# MM32SPIN0230 register map
Series: ARM Cortex M0; File version: 1.0
ARM 32-bit Cortex-M0 based device.
CPU: CM0 r0p0, little endian, no MPU, no FPU, 2 interrupt priority bits
Registers are 32-bit, read-write, reset 0x0 unless marked. A register's access mark holds for its fields unless they carry their own. Offsets are from the block's base; lines under a group give offsets from that group; [hi:lo] are bit positions; {n}, {i} and the like mark numbered series; 'fields as' and 'values as' point back to an identical list; <NAME> marks a mode.

## Memory map
0x40000000 TIM2 size 0x400
0x40001000 TIM6 size 0x400
0x40001800 TIM13 size 0x400
0x40003000 IWDG size 0x400
0x40007000 PWR size 0x400
0x40009000 OPAMP1 size 0x400
0x40009400 OPAMP2 size 0x400
0x40010000 SYSCFG size 0x400
0x40010400 EXTI size 0x400
0x40010C00 USART1 size 0x400
0x40012400 ADC1 size 0x400
0x40012C00 TIM1 size 0x400
0x40013400 DBGMCU size 0x400
0x40013C00 COMP size 0x400
0x40014000 TIM14 size 0x400
0x40020000 DMA size 0x400
0x40021000 RCC size 0x400
0x40022000 FLASH size 0x400
0x40030000 HWDIV size 0x400
0x48000000 GPIOA size 0x400
0x48000400 GPIOB size 0x400

## Interrupts
0 IWDG — independent watchdog interrupt connected to EXTI24
3 FLASH — Flash global interrupt
4 RCC — RCC global interrupt
5 EXTI0_1 (EXTI) — EXTI line [1:0] interrupt
6 EXTI3_2 (EXTI) — EXTI line [3:2] interrupt
7 EXTI15_4 (EXTI) — EXTI line [15:4] interrupt
8 HWDIV — Hard_Divider interrupt
9 DMA1_CH1 (DMA) — DMA1 channel 1 global interrupt
10 DMA1_CH3_CH2 (DMA) — DMA1 channel [3:2] global interrupt
13 TIM1_BRK_UP_TRG_COM (TIM1) — TIM1 break, update, trigger, COM interrupt
14 TIM1_CC (TIM1) — TIM1 capture compare interrupt
15 TIM2 — TIM2 global interrupt
16 TIM6 — TIM6 global interrupt
21 TIM13 — TIM13 global interrupt
22 TIM14 — TIM14 global interrupt
25 COMP1_2 (COMP) — Comparator 1/2 output connected to EXTI19 and EXTI20
28 USART1 — USART1 global interrupt

## ADC1
Base 0x40012400
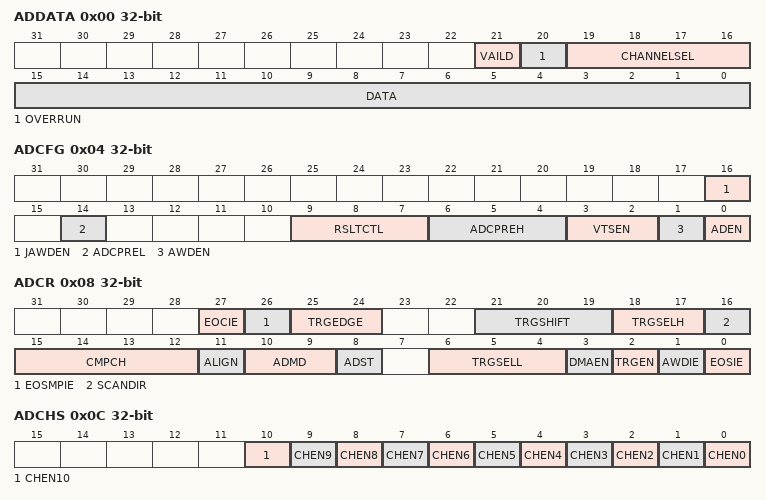
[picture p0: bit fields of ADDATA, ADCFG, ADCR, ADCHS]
0x00 ADDATA ro — Data Register
  [21] VAILD, [20] OVERRUN, [19:16] CHANNELSEL, [15:0] DATA
0x04 ADCFG — Configuration Register
  [16] JAWDEN, [14] ADCPREL, [9:7] RSLTCTL, [6:4] ADCPREH, [3:2] VTSEN, [1] AWDEN, [0] ADEN
0x08 ADCR — Control Register
  [27] EOCIE, [26] EOSMPIE, [25:24] TRGEDGE, [21:19] TRGSHIFT, [18:17] TRGSELH, [16] SCANDIR, [15:12] CMPCH, [11] ALIGN, [10:9] ADMD, [8] ADST, [6:4] TRGSELL, [3] DMAEN, [2] TRGEN, [1] AWDIE, [0] EOSIE
0x0C ADCHS — Channel Selection Register
  [n] CHEN{n} (n=0..10)
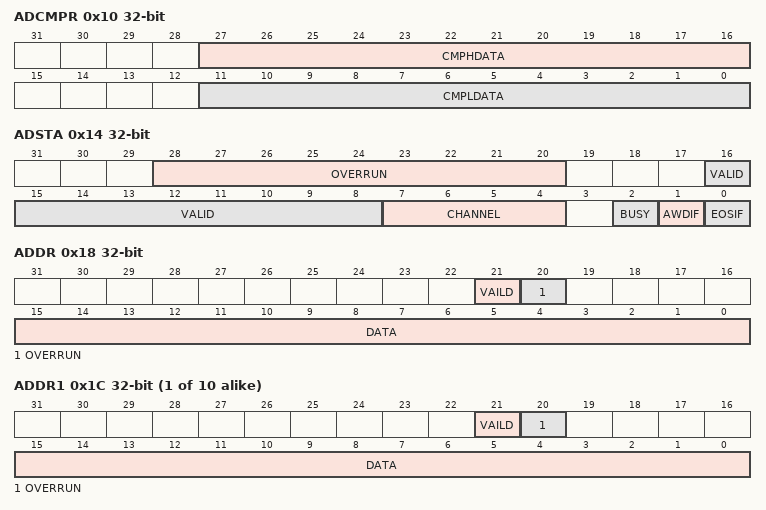
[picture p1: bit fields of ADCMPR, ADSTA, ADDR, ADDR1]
0x10 ADCMPR — Analog Watchdog Compare Register
  [27:16] CMPHDATA, [11:0] CMPLDATA
0x14 ADSTA — Status Register
  [28:20] OVERRUN ro, [16:8] VALID ro, [7:4] CHANNEL ro, [2] BUSY ro, [1] AWDIF write-1-clears, [0] EOSIF write-1-clears
0x18 ADDR ro — Channel Data Register
  [21] VAILD, [20] OVERRUN, [15:0] DATA
{0x18+4i} ADDR{i} ro (i=1..10) — Channel Data Register
  [21] VAILD, [20] OVERRUN, [15:0] DATA
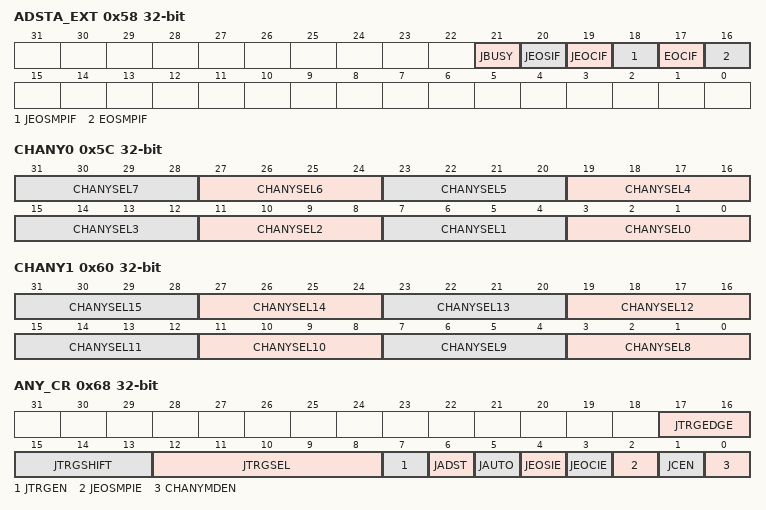
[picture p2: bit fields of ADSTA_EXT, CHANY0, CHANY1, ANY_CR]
0x58 ADSTA_EXT — Extended State Register
  [21] JBUSY ro, [20] JEOSIF write-1-clears, [19] JEOCIF write-1-clears, [18] JEOSMPIF write-1-clears, [17] EOCIF write-1-clears, [16] EOSMPIF write-1-clears
0x5C CHANY0 — Any Channel Selection Register 0
  [4n+3:4n] CHANYSEL{n} (n=0..7)
0x60 CHANY1 — Any Channel Selection Register 1
  [4n-29:4n-32] CHANYSEL{n} (n=8..15)
0x64 ANY_CFG — Any Channel Configuration Register
  [3:0] CHANYNUM
0x68 ANY_CR — Any Channel Control Register
  [17:16] JTRGEDGE, [15:13] JTRGSHIFT, [12:8] JTRGSEL, [7] JTRGEN, [6] JADST, [5] JAUTO, [4] JEOSIE, [3] JEOCIE, [2] JEOSMPIE, [1] JCEN, [0] CHANYMDEN
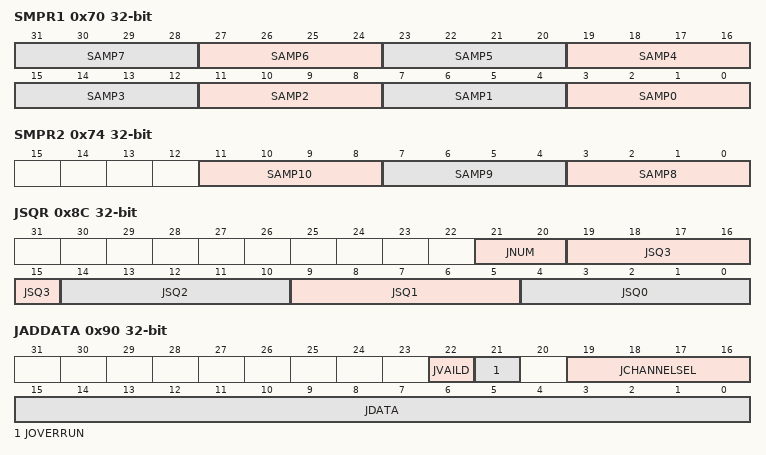
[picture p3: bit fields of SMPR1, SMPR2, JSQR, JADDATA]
0x70 SMPR1 — Sample Configuration Register 1
  [4n+3:4n] SAMP{n} (n=0..7)
0x74 SMPR2 — Sample Configuration Register 2
  [11:8] SAMP10, [7:4] SAMP9, [3:0] SAMP8
0x7C JOFR — Injected Channel Data Offset Register
  [11:0] JOFFSET
{0x7C+4i} JOFR{i} (i=1..3) — Injected Channel Data Offset Register
  [11:0] JOFFSET
0x8C JSQR — Injected Sequence Register
  [21:20] JNUM, [5n+4:5n] JSQ{n} (n=0..3)
0x90 JADDATA ro — Injected Data Register
  [22] JVAILD, [21] JOVERRUN, [19:16] JCHANNELSEL, [15:0] JDATA
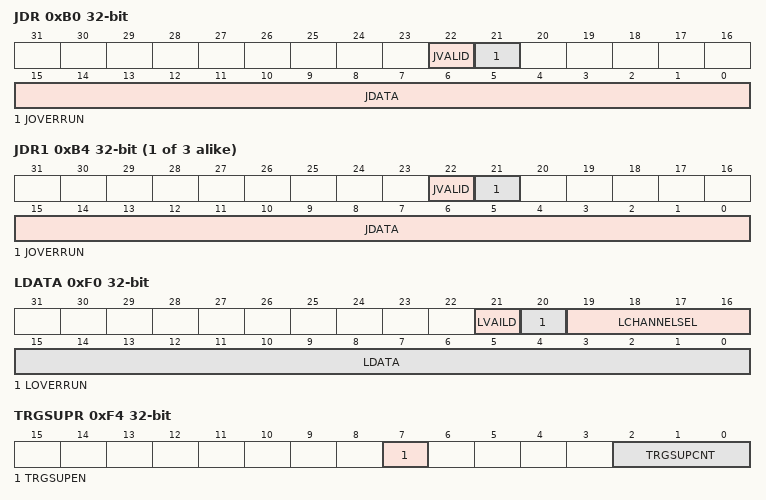
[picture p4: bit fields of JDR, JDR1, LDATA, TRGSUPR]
0xB0 JDR ro — Injected Channel Data Register
  [22] JVALID, [21] JOVERRUN, [15:0] JDATA
{0xB0+4i} JDR{i} ro (i=1..3) — Injected Channel Data Register
  [22] JVALID, [21] JOVERRUN, [15:0] JDATA
0xF0 LDATA ro — Last Conversion Data Register
  [21] LVAILD, [20] LOVERRUN, [19:16] LCHANNELSEL, [15:0] LDATA
0xF4 TRGSUPR — External Rule Trigger Event Suppression Register
  [7] TRGSUPEN, [2:0] TRGSUPCNT
